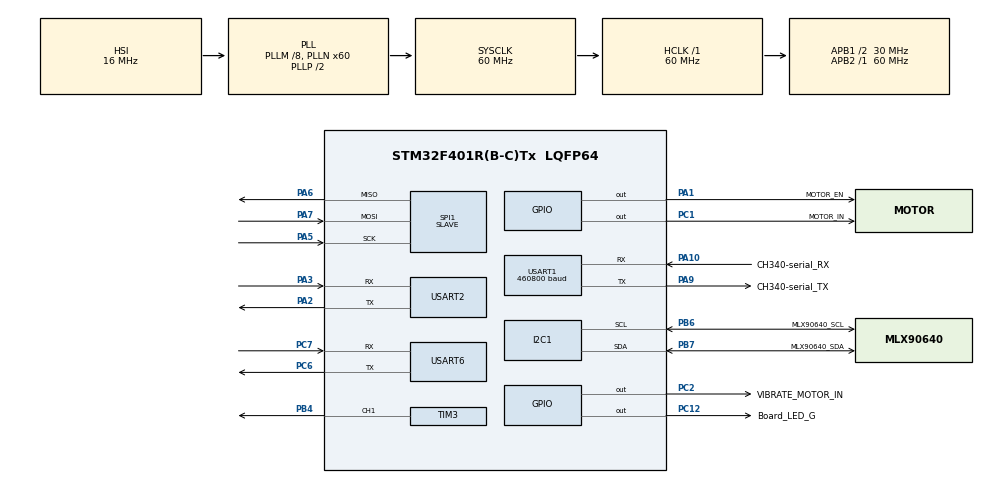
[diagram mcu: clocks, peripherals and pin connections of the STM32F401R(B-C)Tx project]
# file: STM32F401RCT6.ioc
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Dma.Request0=USART1_RX
Dma.Request1=USART1_TX
Dma.Request2=USART2_RX
Dma.Request3=USART2_TX
Dma.USART1_RX.0.Direction=DMA_PERIPH_TO_MEMORY
Dma.USART1_RX.0.FIFOMode=DMA_FIFOMODE_DISABLE
Dma.USART1_RX.0.Instance=DMA2_Stream2
Dma.USART1_RX.0.MemDataAlignment=DMA_MDATAALIGN_BYTE
Dma.USART1_RX.0.MemInc=DMA_MINC_ENABLE
Dma.USART1_RX.0.Mode=DMA_NORMAL
Dma.USART1_RX.0.PeriphDataAlignment=DMA_PDATAALIGN_BYTE
Dma.USART1_RX.0.PeriphInc=DMA_PINC_DISABLE
Dma.USART1_RX.0.Priority=DMA_PRIORITY_MEDIUM
Dma.USART1_TX.1.Direction=DMA_MEMORY_TO_PERIPH
Dma.USART1_TX.1.FIFOMode=DMA_FIFOMODE_DISABLE
Dma.USART1_TX.1.Instance=DMA2_Stream7
Dma.USART1_TX.1.MemDataAlignment=DMA_MDATAALIGN_BYTE
Dma.USART1_TX.1.MemInc=DMA_MINC_ENABLE
Dma.USART1_TX.1.Mode=DMA_NORMAL
Dma.USART1_TX.1.PeriphDataAlignment=DMA_PDATAALIGN_BYTE
Dma.USART1_TX.1.PeriphInc=DMA_PINC_DISABLE
Dma.USART1_TX.1.Priority=DMA_PRIORITY_MEDIUM
Dma.USART2_RX.2.Direction=DMA_PERIPH_TO_MEMORY
Dma.USART2_RX.2.FIFOMode=DMA_FIFOMODE_DISABLE
Dma.USART2_RX.2.Instance=DMA1_Stream5
Dma.USART2_RX.2.MemDataAlignment=DMA_MDATAALIGN_BYTE
Dma.USART2_RX.2.MemInc=DMA_MINC_ENABLE
Dma.USART2_RX.2.Mode=DMA_NORMAL
Dma.USART2_RX.2.PeriphDataAlignment=DMA_PDATAALIGN_BYTE
Dma.USART2_RX.2.PeriphInc=DMA_PINC_DISABLE
Dma.USART2_RX.2.Priority=DMA_PRIORITY_LOW
Dma.USART2_TX.3.Direction=DMA_MEMORY_TO_PERIPH
Dma.USART2_TX.3.FIFOMode=DMA_FIFOMODE_DISABLE
Dma.USART2_TX.3.Instance=DMA1_Stream6
Dma.USART2_TX.3.MemDataAlignment=DMA_MDATAALIGN_BYTE
Dma.USART2_TX.3.MemInc=DMA_MINC_ENABLE
Dma.USART2_TX.3.Mode=DMA_NORMAL
Dma.USART2_TX.3.PeriphDataAlignment=DMA_PDATAALIGN_BYTE
Dma.USART2_TX.3.PeriphInc=DMA_PINC_DISABLE
Dma.USART2_TX.3.Priority=DMA_PRIORITY_LOW
Mcu.Family=STM32F4
Mcu.Name=STM32F401R(B-C)Tx
Mcu.Package=LQFP64
NVIC.DMA1_Stream5_IRQn=true\:0\:0\:false\:false\:true\:false\:true\:true
NVIC.DMA1_Stream6_IRQn=true\:0\:0\:false\:false\:true\:false\:true\:true
NVIC.DMA2_Stream2_IRQn=true\:0\:0\:false\:false\:true\:false\:true\:true
NVIC.DMA2_Stream7_IRQn=true\:0\:0\:false\:false\:true\:false\:true\:true
NVIC.PriorityGroup=NVIC_PRIORITYGROUP_4
NVIC.USART1_IRQn=true\:0\:0\:false\:false\:true\:true\:true\:true
NVIC.USART2_IRQn=true\:0\:0\:false\:false\:true\:true\:true\:true
PA1.GPIO_Label=MOTOR_EN
PA1.Signal=GPIO_Output
PA10.GPIO_Label=CH340-serial_RX
PA10.Mode=Asynchronous
PA10.Signal=USART1_RX
PA13.Mode=Serial_Wire
PA13.Signal=SYS_JTMS-SWDIO
PA14.Mode=Serial_Wire
PA14.Signal=SYS_JTCK-SWCLK
PA2.Mode=Asynchronous
PA2.Signal=USART2_TX
PA3.Mode=Asynchronous
PA3.Signal=USART2_RX
PA5.Mode=Full_Duplex_Slave
PA5.Signal=SPI1_SCK
PA6.Mode=Full_Duplex_Slave
PA6.Signal=SPI1_MISO
PA7.Mode=Full_Duplex_Slave
PA7.Signal=SPI1_MOSI
PA9.GPIO_Label=CH340-serial_TX
PA9.Mode=Asynchronous
PA9.Signal=USART1_TX
PB4.Signal=S_TIM3_CH1
PB6.GPIO_Label=MLX90640_SCL
PB6.Mode=I2C
PB6.Signal=I2C1_SCL
PB7.GPIO_Label=MLX90640_SDA
PB7.Mode=I2C
PB7.Signal=I2C1_SDA
PC1.GPIO_Label=MOTOR_IN
PC1.Signal=GPIO_Output
PC12.GPIO_Label=Board_LED_G
PC12.Signal=GPIO_Output
PC2.GPIO_Label=VIBRATE_MOTOR_IN
PC2.Signal=GPIO_Output
PC6.Mode=Asynchronous
PC6.Signal=USART6_TX
PC7.Mode=Asynchronous
PC7.Signal=USART6_RX
PH0\ -\ OSC_IN.Mode=HSE-External-Oscillator
PH0\ -\ OSC_IN.Signal=RCC_OSC_IN
PH1\ -\ OSC_OUT.Mode=HSE-External-Oscillator
PH1\ -\ OSC_OUT.Signal=RCC_OSC_OUT
ProjectManager.HeapSize=0x200
ProjectManager.StackSize=0x400
ProjectManager.TargetToolchain=CMake
RCC.48MHZClocksFreq_Value=30000000
RCC.AHBFreq_Value=60000000
RCC.APB1CLKDivider=RCC_HCLK_DIV2
RCC.APB1Freq_Value=30000000
RCC.APB1TimFreq_Value=60000000
RCC.APB2Freq_Value=60000000
RCC.APB2TimFreq_Value=60000000
RCC.CortexFreq_Value=60000000
RCC.HCLKFreq_Value=60000000
RCC.HSE_VALUE=25000000
RCC.HSI_VALUE=16000000
RCC.LSE_VALUE=32768
RCC.PLLM=8
RCC.PLLN=60
RCC.SYSCLKFreq_VALUE=60000000
RCC.SYSCLKSource=RCC_SYSCLKSOURCE_PLLCLK
RCC.VCOOutputFreq_Value=120000000
SH.S_TIM3_CH1.0=TIM3_CH1,PWM Generation1 CH1
SPI1.Direction=SPI_DIRECTION_2LINES
SPI1.Mode=SPI_MODE_SLAVE
SPI1.VirtualType=VM_SLAVE
TIM3.Channel-PWM\ Generation1\ CH1=TIM_CHANNEL_1
USART1.BaudRate=460800
USART1.VirtualMode=VM_ASYNC
USART2.VirtualMode=VM_ASYNC
USART6.VirtualMode=VM_ASYNC
VP_RTC_VS_RTC_Activate.Mode=RTC_Enabled
board=custom

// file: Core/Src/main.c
/* USER CODE BEGIN Header */
/**
 ******************************************************************************
 * @file           : 使用stm32f401rct6作为从机
 * @brief          : main.c主程序入口
 ******************************************************************************
 * @attention
 *
 * Copyright (c) 2025 STMicroelectronics.
 * All rights reserved.
 *
 * This software is licensed under terms that can be found in the LICENSE file
 * in the root directory of this software component.
 * If no LICENSE file comes with this software, it is provided AS-IS.
 *
 ******************************************************************************
 */
/* USER CODE END Header */
#include "main.h"
#include "dma.h"
#include "i2c.h"
#include "rtc.h"
#include "spi.h"
#include "tim.h"
#include "usart.h"
#include "gpio.h"

/* USER CODE BEGIN Includes */
#include "tempra.h"
#include "motor.h"
#include "receive.h"
/* USER CODE END Includes */

void SystemClock_Config(void);

/* USER CODE BEGIN 0 */

/*
MCU:stm32f401RCT6
usart2_rx-----mlx90640_tx
usart1_tx-----ft232_rx
*/

/* USER CODE END 0 */

int main(void)
{

  /* MCU Configuration--------------------------------------------------------*/

  /* Reset of all peripherals, Initializes the Flash interface and the Systick. */
  HAL_Init();

  /* Configure the system clock */
  SystemClock_Config();

  /* Initialize all configured peripherals */
  MX_GPIO_Init();
  MX_DMA_Init();
  MX_USART2_UART_Init();
  MX_USART6_UART_Init();
  MX_SPI1_Init();
  MX_I2C1_Init();
  MX_USART1_UART_Init();
  MX_RTC_Init();
  MX_TIM3_Init();

  /* Infinite loop */
  /* USER CODE BEGIN WHILE */
  while (1)
  {
    receive();
    // 此处实现电机启停
    if (allow == 0 && tempra == 0) // 判断从机的报警数值和热成像符合条件
    {
      // 电机启动
      ALL_MOTOR_START();
      // TODO: 此处tim3实现pwm调速
    }
    else if (allow == 1 && tempra == 0)
    {
      // 手动触发报警，电机停止
      ALL_MOTOR_STOP();
    }
    else if (allow == 1 && tempra == 1)
    {
      // 触发报警，电机停止
      ALL_MOTOR_STOP();
    }
  }
    /* USER CODE END WHILE */

}

void SystemClock_Config(void)
{
  RCC_OscInitTypeDef RCC_OscInitStruct = {0};
  RCC_ClkInitTypeDef RCC_ClkInitStruct = {0};

  /** Configure the main internal regulator output voltage
  */
  __HAL_RCC_PWR_CLK_ENABLE();
  __HAL_PWR_VOLTAGESCALING_CONFIG(PWR_REGULATOR_VOLTAGE_SCALE2);

  /** Initializes the RCC Oscillators according to the specified parameters
  * in the RCC_OscInitTypeDef structure.
  */
  RCC_OscInitStruct.OscillatorType = RCC_OSCILLATORTYPE_HSI|RCC_OSCILLATORTYPE_LSI;
  RCC_OscInitStruct.HSIState = RCC_HSI_ON;
  RCC_OscInitStruct.HSICalibrationValue = RCC_HSICALIBRATION_DEFAULT;
  RCC_OscInitStruct.LSIState = RCC_LSI_ON;
  RCC_OscInitStruct.PLL.PLLState = RCC_PLL_ON;
  RCC_OscInitStruct.PLL.PLLSource = RCC_PLLSOURCE_HSI;
  RCC_OscInitStruct.PLL.PLLM = 8;
  RCC_OscInitStruct.PLL.PLLN = 60;
  RCC_OscInitStruct.PLL.PLLP = RCC_PLLP_DIV2;
  RCC_OscInitStruct.PLL.PLLQ = 4;
  if (HAL_RCC_OscConfig(&RCC_OscInitStruct) != HAL_OK)
  {
    Error_Handler();
  }

  /** Initializes the CPU, AHB and APB buses clocks
  */
  RCC_ClkInitStruct.ClockType = RCC_CLOCKTYPE_HCLK|RCC_CLOCKTYPE_SYSCLK
                              |RCC_CLOCKTYPE_PCLK1|RCC_CLOCKTYPE_PCLK2;
  RCC_ClkInitStruct.SYSCLKSource = RCC_SYSCLKSOURCE_PLLCLK;
  RCC_ClkInitStruct.AHBCLKDivider = RCC_SYSCLK_DIV1;
  RCC_ClkInitStruct.APB1CLKDivider = RCC_HCLK_DIV2;
  RCC_ClkInitStruct.APB2CLKDivider = RCC_HCLK_DIV1;

  if (HAL_RCC_ClockConfig(&RCC_ClkInitStruct, FLASH_LATENCY_1) != HAL_OK)
  {
    Error_Handler();
  }
}

void Error_Handler(void)
{
  __disable_irq();
  while (1)
  {
  }
}
